# nrf9230_enga_sysctrl register map
Vendor: Nordic Semiconductor; Series: nRF92; File version: 1
Registers are 32-bit, read-write, reset 0x0 unless marked. A register's access mark holds for its fields unless they carry their own. Offsets are from the block's base; [hi:lo] are bit positions; lines under a group give offsets from that group; {n}, {i} and the like mark numbered series; 'fields as' and 'values as' point back to an identical list.

## HFXO64M — HFXO64M peripheral
Base 0x5F955000
0x100 EVENTS_STARTED — HFXO64M started
  [0] EVENTS_STARTED
    0=NotGenerated (Event not generated); 1=Generated (Event generated)
0x104 EVENTS_STOPPED — HFXO64M stopped
  [0] EVENTS_STOPPED
    values as EVENTS_STARTED.EVENTS_STARTED
0x108 EVENTS_ERRORBIAS — Error with BIAS setup
  [0] EVENTS_ERRORBIAS
    values as EVENTS_STARTED.EVENTS_STARTED
0x10C EVENTS_ERRORDETECTOR — Error with DETECTOR
  [0] EVENTS_ERRORDETECTOR
    values as EVENTS_STARTED.EVENTS_STARTED
0x110 EVENTS_ERRORTCXO — Error with TCXO startup
  [0] EVENTS_ERRORTCXO
    values as EVENTS_STARTED.EVENTS_STARTED
0x114 EVENTS_STARTREQ — Clock start has been requested
  [0] EVENTS_STARTREQ
    values as EVENTS_STARTED.EVENTS_STARTED
0x118 EVENTS_STOPREQ — Clock stop has been requested
  [0] EVENTS_STOPREQ
    values as EVENTS_STARTED.EVENTS_STARTED
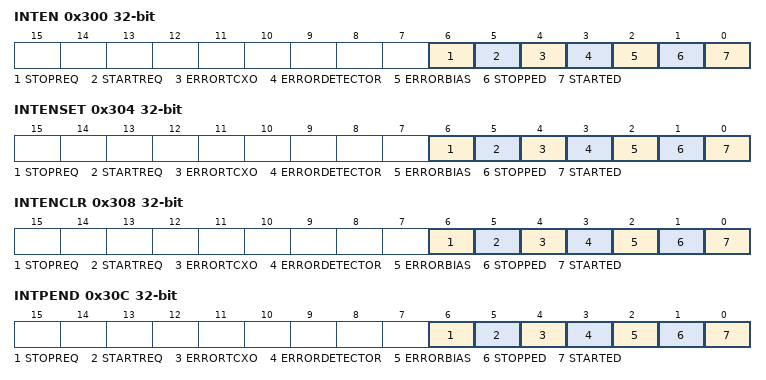
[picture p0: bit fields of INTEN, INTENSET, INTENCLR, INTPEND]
0x300 INTEN — Enable or disable interrupt
  [all] fields
    0=Disabled; 1=Enabled
  [6] STOPREQ — Enable or disable interrupt for event STOPREQ
  [5] STARTREQ — Enable or disable interrupt for event STARTREQ
  [4] ERRORTCXO — Enable or disable interrupt for event ERRORTCXO
  [3] ERRORDETECTOR — Enable or disable interrupt for event ERRORDETECTOR
  [2] ERRORBIAS — Enable or disable interrupt for event ERRORBIAS
  [1] STOPPED — Enable or disable interrupt for event STOPPED
  [0] STARTED — Enable or disable interrupt for event STARTED
0x304 INTENSET — Enable interrupt
  [all] fields
    on read: 0=Disabled (Read: Disabled); 1=Enabled (Read: Enabled) | on write: 1=Set (Enable)
  [6] STOPREQ — Write '1' to enable interrupt for event STOPREQ
  [5] STARTREQ — Write '1' to enable interrupt for event STARTREQ
  [4] ERRORTCXO — Write '1' to enable interrupt for event ERRORTCXO
  [3] ERRORDETECTOR — Write '1' to enable interrupt for event ERRORDETECTOR
  [2] ERRORBIAS — Write '1' to enable interrupt for event ERRORBIAS
  [1] STOPPED — Write '1' to enable interrupt for event STOPPED
  [0] STARTED — Write '1' to enable interrupt for event STARTED
0x308 INTENCLR — Disable interrupt
  [all] fields
    on read: 0=Disabled (Read: Disabled); 1=Enabled (Read: Enabled) | on write: 1=Clear (Disable)
  [6] STOPREQ — Write '1' to disable interrupt for event STOPREQ
  [5] STARTREQ — Write '1' to disable interrupt for event STARTREQ
  [4] ERRORTCXO — Write '1' to disable interrupt for event ERRORTCXO
  [3] ERRORDETECTOR — Write '1' to disable interrupt for event ERRORDETECTOR
  [2] ERRORBIAS — Write '1' to disable interrupt for event ERRORBIAS
  [1] STOPPED — Write '1' to disable interrupt for event STOPPED
  [0] STARTED — Write '1' to disable interrupt for event STARTED
0x30C INTPEND ro — Pending interrupts
  [all] fields
    on read: 0=NotPending (Read: Not pending); 1=Pending (Read: Pending)
  [6] STOPREQ — Read pending status of interrupt for event STOPREQ
  [5] STARTREQ — Read pending status of interrupt for event STARTREQ
  [4] ERRORTCXO — Read pending status of interrupt for event ERRORTCXO
  [3] ERRORDETECTOR — Read pending status of interrupt for event ERRORDETECTOR
  [2] ERRORBIAS — Read pending status of interrupt for event ERRORBIAS
  [1] STOPPED — Read pending status of interrupt for event STOPPED
  [0] STARTED — Read pending status of interrupt for event STARTED
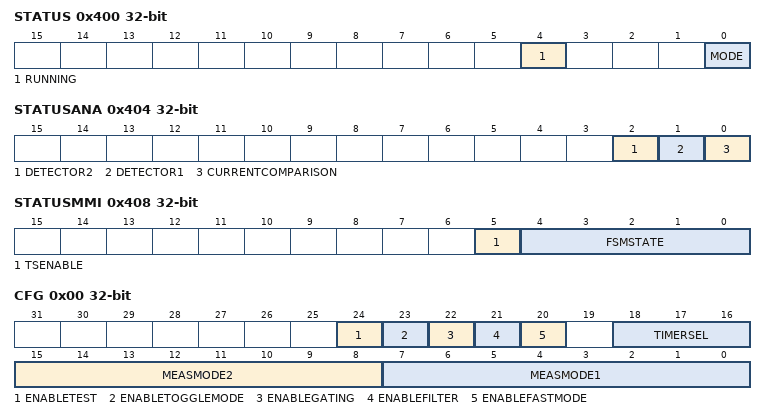
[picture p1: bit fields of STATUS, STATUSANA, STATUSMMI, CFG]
0x400 STATUS ro — HFXO64M status
  [4] RUNNING — HFXO64M running status
    0=NotRunning (HFXO64M not running); 1=Running (HFXO64M running)
  [0] MODE — Current mode
    0=Normal HFXO64M mode; 1=TCXO (External TCXO used, HFXO64M core is bypassed)
0x404 STATUSANA ro — Status of analog module output signals
  [2] DETECTOR2 — Current value of the DETECTOR2 signal from the analog module
  [1] DETECTOR1 — Current value of the DETECTOR1 signal from the analog module
  [0] CURRENTCOMPARISON — Current value of the CURRENT_COMPARISON from the analog module
0x408 STATUSMMI ro — MMI internal values for debug use.
  [5] TSENABLE — TS_ENABLE analog IP pin status. Tells if TS is running.
  [4:0] FSMSTATE — FSM current state. Value must be checked against RTL.
0x440 TRIM group — Unspecified
  0x00 RTUNE — Voltage reference tuning control. 2's complement (MSB bit is inverted). Tuning range is approximately +/-50mV
    [3:0] VAL
  0x04 CHIRPTUNE — This is a process compensation tuning for chirp generator.
    [1:0] VAL
      0=Fast process; 1=Typical process; 2=Slow process
  0x08 DOUBLERCOMP — Process compensation control for frequency doubler.
    [2:0] VAL
      1=Slow process; 3=Typical process; 7=Fast process
0x460 TS group — Unspecified
  0x00 CFG — Temperature sensor static configuration register.
    [24] ENABLETEST — Enables TS test mode.
      0=Disabled; 1=Enabled
    [23] ENABLETOGGLEMODE — Enables continuous toggle if both channels are on.
      0=Disabled; 1=Enabled
    [22] ENABLEGATING — Enables continuous comparison/disables comparator current saving
      0=Disabled; 1=Enabled
    [21] ENABLEFILTER — Enables continuous slow filter.
      0=Disabled; 1=Enabled
    [20] ENABLEFASTMODE — Enables fast slew rate function.
      0=Disabled; 1=Enabled
    [18:16] TIMERSEL — Sets temperature measurement interval
      0=Interval4us (4 us); 1=Interval8us (8 us); 2=Interval16us (16 us); 3=Interval32us (32 us); 4=Interval64us (64 us); 5=Interval128us (128 us); 6=Interval256us (256 us); 7=Interval512us (512 us)
    [15:8] MEASMODE2 — Measurement mode control for ch2.
    [7:0] MEASMODE1 — Measurement mode control for ch1.
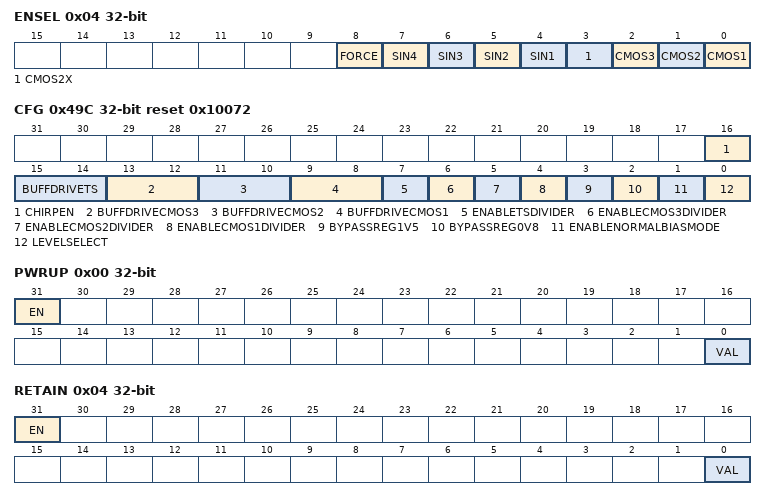
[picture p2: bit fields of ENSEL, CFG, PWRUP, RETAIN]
  0x04 ENSEL — Enable TS per clock request.
    [all] fields
      0=Disabled; 1=Enabled
    [8] FORCE — Force TS on when HFXO64M is powered.
    [n+3] SIN{n} (n=1..4) — Enable TS when SIN{n} is requested.
    [3] CMOS2X — Enable TS when CMOS2X is requested.
    [2] CMOS3 — Enable TS when CMOS3 is requested.
    [1] CMOS2 — Enable TS when CMOS2 is requested.
    [0] CMOS1 — Enable TS when CMOS1 is requested.
  0x08 DATAIN — TS test data input. Used only when debugging
    [15:0] VAL
  0x0C DATAINLOAD — TS test data latch pulse input. Used only when debugging
    [0] VAL
0x480 MIRROR reset 0x1 — Enable LOCK for mirrored registers
  [0] LOCK — Lock for mirrored registers
    0=Disabled (Lock disabled); 1=Enabled (Lock enabled)
0x484 PWRUPCTRL reset 0x2 — Power up control
  [1:0] CTRL
    0=Automatically handled by the peripheral; 1=PowerUp; 2=PowerDown
0x488 MODE — HFXO64M mode
  [0] MODE
    0=Normal operating mode; 1=TCXO (TCXO/bypass mode)
0x48C XTALSETTLETIME reset 0x3 — Settle time of the crystal. List of pre-coded times.
  [3:0] VAL
    0=Settle250us (250 us); 1=Settle300us (300 us); 2=Settle350us (350 us); 3=Settle400us (400 us); 4=Settle500us (500 us); 5=Settle600us (600 us); 6=Settle700us (700 us); 7=Settle800us (800 us); 8=Settle1000us (1000 us); 9=Settle2000us (2000 us); 10=Settle3000us (3000 us); 11=Settle4000us (4000 us); 12=Settle5000us (5000 us); 13=Settle6000us (6000 us); 14=Settle7000us (7000 us); 15=Settle8500us (8500 us)
0x490 CHIRPTIME reset 0x3 — Chirp period length. List of pre-coded times.
  [3:0] VAL
    0=Chirp32us (32.0 us); 1=Chirp40us (40.3 us); 2=Chirp48us (48.5 us); 3=Chirp56us (56.8 us); 4=Chirp65us (65.1 us); 5=Chirp73us (73.3 us); 6=Chirp81us (81.6 us); 7=Chirp89us (89.9 us); 8=Chirp98us (98.1 us); 9=Chirp106us (106.4 us); 10=Chirp114us (114.7 us); 11=Chirp122us (122.9 us); 12=Chirp131us (131.2 us); 13=Chirp139us (139.5 us); 14=Chirp147us (147.7 us); 15=Chirp156us (156.0 us)
0x494 ENABLEDAMPING — Enables the MMI to do crystal damping when stopping the oscillator.
  [0] VAL
    0=Disabled; 1=Enabled
0x498 FORCEBUFF — Enables all clock buffers when sinOut4_ana buffer is enabled.
  [0] VAL
    0=Disabled; 1=Enabled
0x49C CFG reset 0x10072 — Direct HFXO64M static configurations.
  [16] CHIRPEN — Enable chirp during the HFXO64 startup.
    0=Disabled (Chirp disabled); 1=Enabled (Chirp enabled)
  [15:14] BUFFDRIVETS — Buffer drive configuration for TS clock
  [13:12] BUFFDRIVECMOS3 — Buffer drive configuration for CMOS_OUT3
  [11:10] BUFFDRIVECMOS2 — Buffer drive configuration for CMOS_OUT2
  [9:8] BUFFDRIVECMOS1 — Buffer drive configuration for CMOS_OUT1
  [7] ENABLETSDIVIDER — TS clock divider enable.
    0=Disabled; 1=Enabled
  [6] ENABLECMOS3DIVIDER — CMOSOUT3 clock divider enable.
    0=Disabled; 1=Enabled
  [5] ENABLECMOS2DIVIDER — CMOSOUT2 clock divider enable.
    0=Disabled; 1=Enabled
  [4] ENABLECMOS1DIVIDER — CMOSOUT1 clock divider enable.
    0=Disabled; 1=Enabled
  [3] BYPASSREG1V5 — 1V5 regulator bypass control.
    0=Normal; 1=Bypass
  [2] BYPASSREG0V8 — 0V8 regulator bypass control.
    0=Normal; 1=Bypass
  [1] ENABLENORMALBIASMODE — Enable for normal bias mode.
    0=Low (Low power bias mode); 1=Normal bias mode
  [0] LEVELSELECT — Select for AREG level
    0=High (Normal, high amplitude); 1=Low (Low power, low amplitude)
0x4A0 TCXOPOWERED — SysCtrl writes here the current status of the TCXO power.
  [0] VAL
    0=Off (TCXO is powered off); 1=On (TCXO is powered on)
0x500 OVERRIDE group — Unspecified
  0x00 PWRUP — PWRUP override
    [31] EN, [0] VAL
  0x04 RETAIN — RETAIN override
    [31] EN, [0] VAL
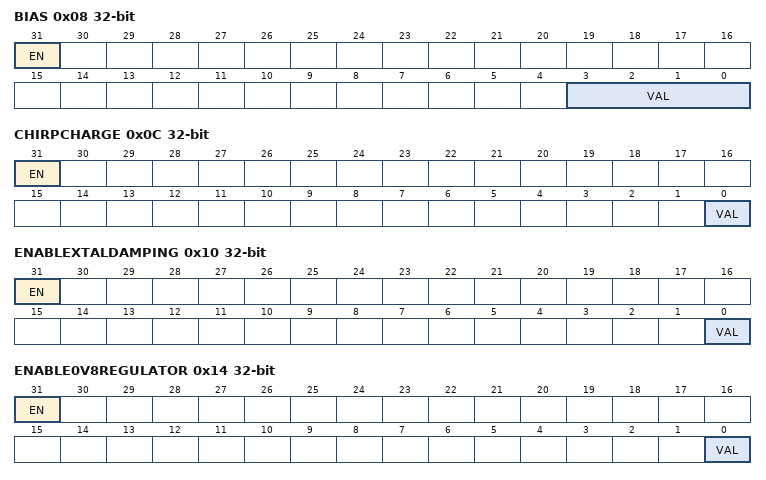
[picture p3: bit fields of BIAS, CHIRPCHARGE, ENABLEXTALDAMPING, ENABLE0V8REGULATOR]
  0x08 BIAS — BIAS override
    [31] EN, [3:0] VAL
  0x0C CHIRPCHARGE — CHIRP_CHARGE override
    [31] EN, [0] VAL
  0x10 ENABLEXTALDAMPING — ENABLE_XTAL_DAMPING override
    [31] EN, [0] VAL
  0x14 ENABLE0V8REGULATOR — ENABLE_0V8_REGULATOR override
    [31] EN, [0] VAL
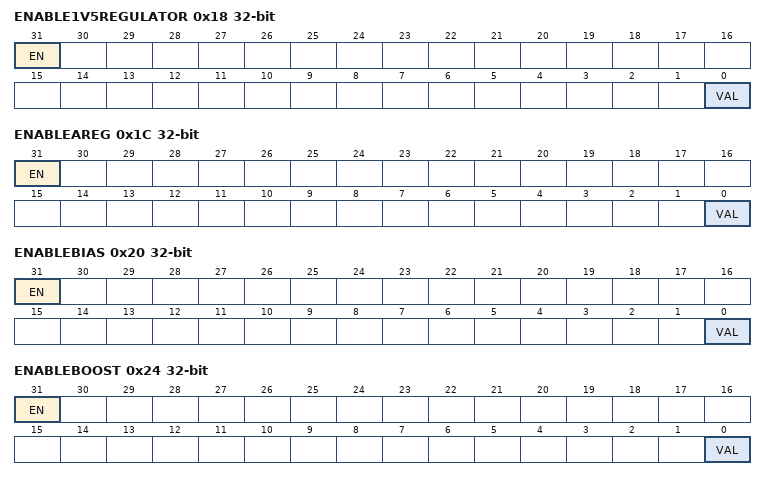
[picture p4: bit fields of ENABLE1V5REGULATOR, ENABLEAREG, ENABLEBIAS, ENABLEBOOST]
  0x18 ENABLE1V5REGULATOR — ENABLE_1V5_REGULATOR override
    [31] EN, [0] VAL
  0x1C ENABLEAREG — ENABLE_AREG override
    [31] EN, [0] VAL
  0x20 ENABLEBIAS — ENABLE_BIAS override
    [31] EN, [0] VAL
  0x24 ENABLEBOOST — ENABLE_BOOST override
    [31] EN, [0] VAL
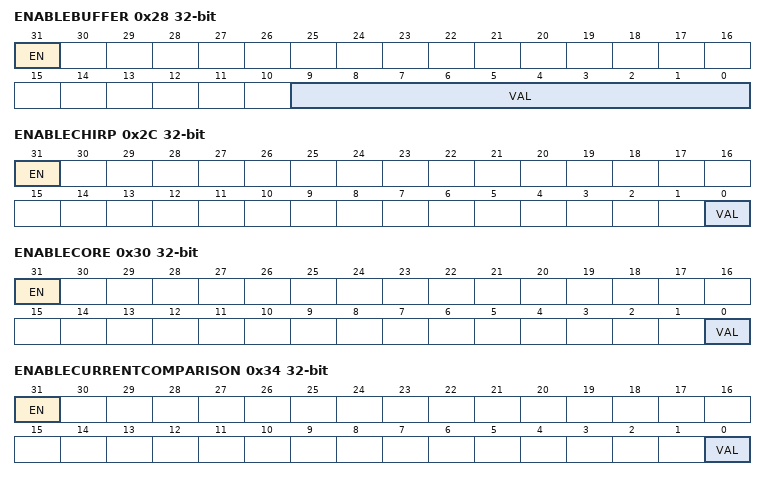
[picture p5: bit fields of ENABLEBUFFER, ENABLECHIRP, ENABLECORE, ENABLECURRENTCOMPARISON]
  0x28 ENABLEBUFFER — ENABLE_BUFFER override
    [31] EN, [9:0] VAL
  0x2C ENABLECHIRP — ENABLE_CHIRP override
    [31] EN, [0] VAL
  0x30 ENABLECORE — ENABLE_CORE override
    [31] EN, [0] VAL
  0x34 ENABLECURRENTCOMPARISON — ENABLE_CURRENT_COMPARISON override
    [31] EN, [0] VAL
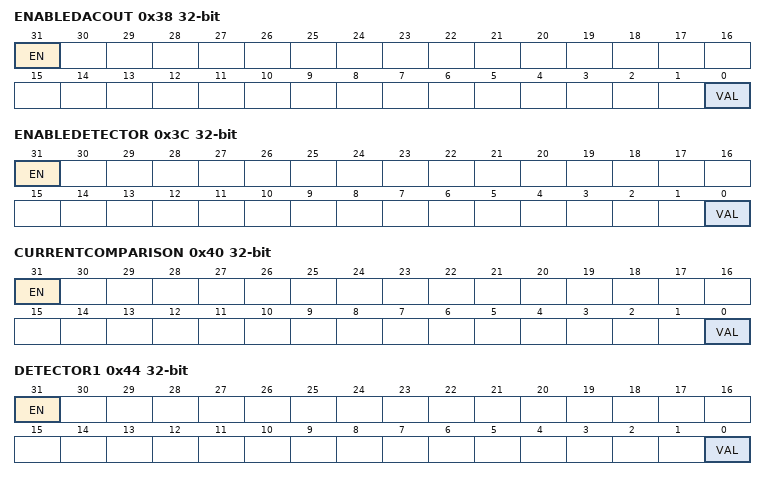
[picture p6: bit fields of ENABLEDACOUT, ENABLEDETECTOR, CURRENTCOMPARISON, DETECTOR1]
  0x38 ENABLEDACOUT — ENABLE_DAC_OUT override
    [31] EN, [0] VAL
  0x3C ENABLEDETECTOR — ENABLE_DETECTOR override
    [31] EN, [0] VAL
  0x40 CURRENTCOMPARISON — CURRENT_COMPARISON override
    [31] EN, [0] VAL
  0x44 DETECTOR1 — DETECTOR1 override
    [31] EN, [0] VAL
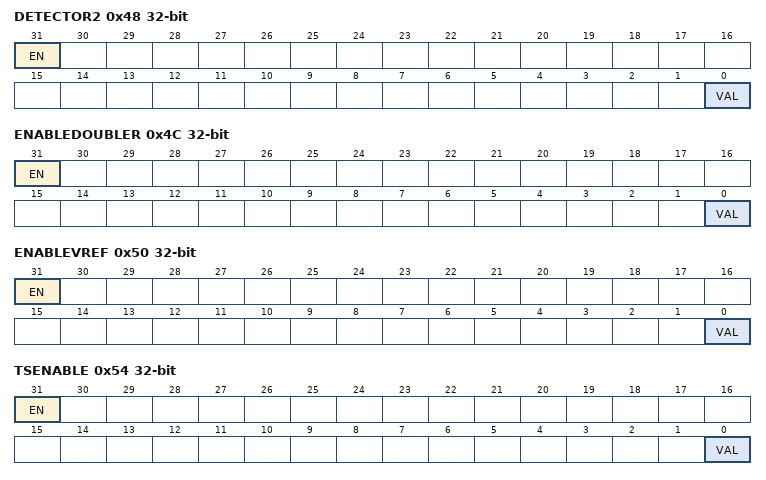
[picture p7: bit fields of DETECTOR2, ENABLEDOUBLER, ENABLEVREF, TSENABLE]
  0x48 DETECTOR2 — DETECTOR2 override
    [31] EN, [0] VAL
  0x4C ENABLEDOUBLER — ENABLE_DOUBLER override
    [31] EN, [0] VAL
  0x50 ENABLEVREF — ENABLE_VREF override
    [31] EN, [0] VAL
  0x54 TSENABLE — TSENABLE override
    [31] EN, [0] VAL
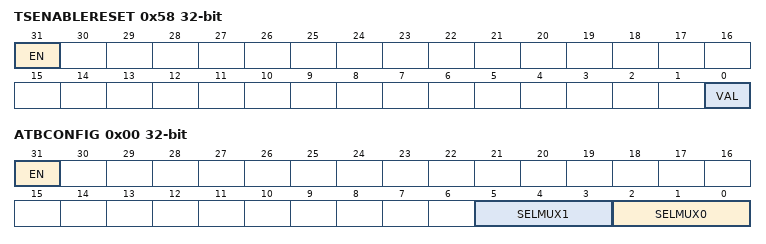
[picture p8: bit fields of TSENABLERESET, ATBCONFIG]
  0x58 TSENABLERESET — TSENABLERESET override
    [31] EN, [0] VAL
0x600 DFT group — Unspecified
  0x00 ATBCONFIG — ATB0 and ATB1 test mux control.
    [31] EN
      0=Disabled (Analog test busses are disabled.); 1=Enabled (Analog test busses are enabled.)
    [5:3] SELMUX1 — Test mux control for ATB1.
      0=None (Nothing selected.); 1=VAteg (AREG block test voltage. Xo level dependent.); 2=VChirp (Chirp generator test voltage.); 3=VTS (Temp Sensor test voltage.); 4=VGnd (Connected to XO VSS/ground. Use as reference voltage for GND.)
    [2:0] SELMUX0 — Test mux control for ATB0.
      0=None (Nothing selected.); 1=Vref (Voltage reference output. Approximately 0.76V); 2=V1v5Reg (1.5V regulator output voltage.); 3=V0V8Reg (0.8V regulator output voltage.); 4=VPierce (IPIERCE voltage. XO core imminent supply voltage.)
